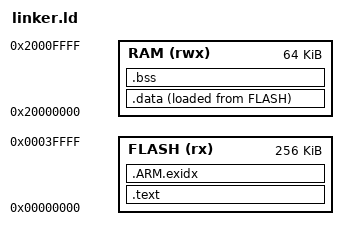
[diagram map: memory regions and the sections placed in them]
/*
 * linker.ld — Cortex-M genérico: flash em 0 (vetores primeiro), RAM em
 * 0x20000000. Valores do QEMU mps2-an385 (SSRAM1 em 0, SSRAM2/3 em
 * 0x20000000), reduzidos ao porte de um MCU típico.
 */
MEMORY
{
    FLASH (rx)  : ORIGIN = 0x00000000, LENGTH = 256K
    RAM   (rwx) : ORIGIN = 0x20000000, LENGTH = 64K
}

ENTRY(Reset_Handler)

SECTIONS
{
    .text :
    {
        KEEP(*(.isr_vector))
        *(.text*)
        *(.rodata*)
        . = ALIGN(4);
    } > FLASH

    .ARM.exidx :
    {
        *(.ARM.exidx*)
    } > FLASH

    _sidata = LOADADDR(.data);

    .data :
    {
        . = ALIGN(4);
        _sdata = .;
        *(.data*)
        . = ALIGN(4);
        _edata = .;
    } > RAM AT > FLASH

    .bss (NOLOAD) :
    {
        . = ALIGN(4);
        _sbss = .;
        *(.bss*)
        *(COMMON)
        . = ALIGN(4);
        _ebss = .;
    } > RAM

    _estack = ORIGIN(RAM) + LENGTH(RAM);
}
